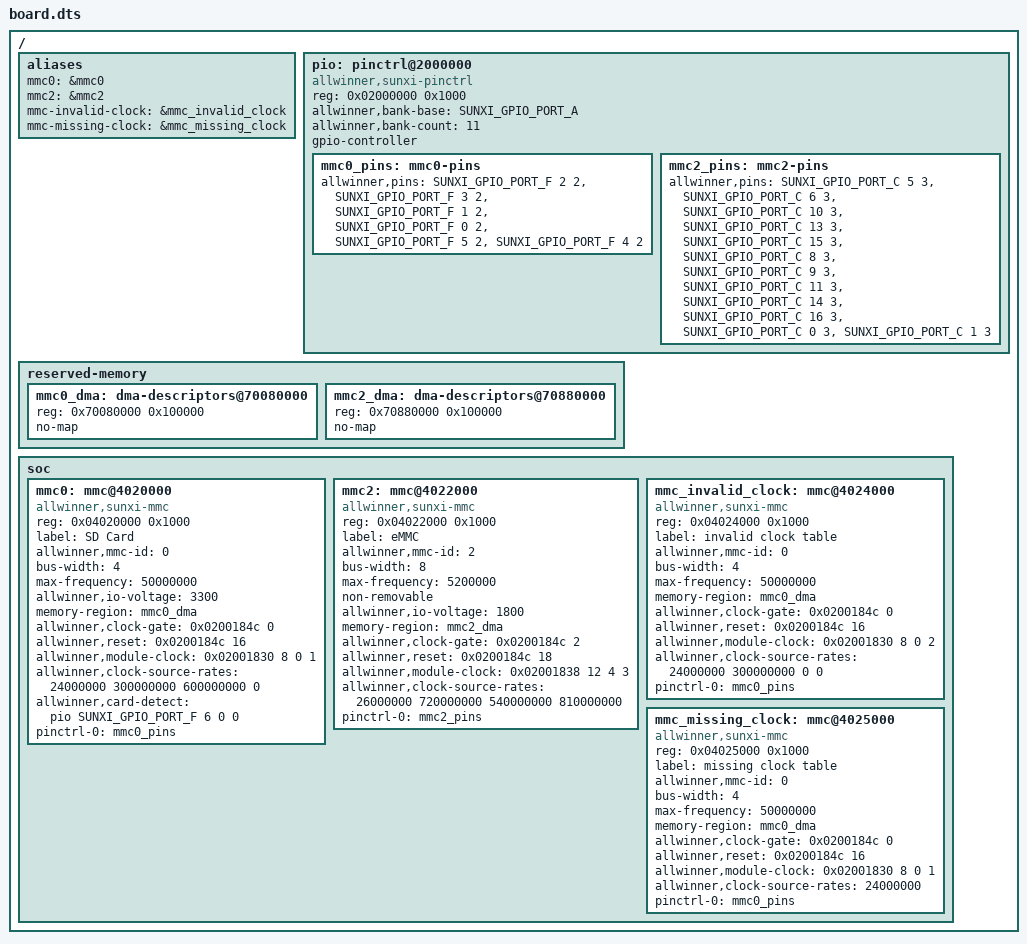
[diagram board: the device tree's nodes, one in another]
/dts-v1/;

#include <dt-bindings/gpio/sunxi-gpio.h>

/ {
	#address-cells = <1>;
	#size-cells = <1>;

		aliases {
			mmc0 = &mmc0;
			mmc2 = &mmc2;
			mmc-invalid-clock = &mmc_invalid_clock;
			mmc-missing-clock = &mmc_missing_clock;
	};

	pio: pinctrl@2000000 {
		compatible = "allwinner,sunxi-pinctrl";
		reg = <0x02000000 0x1000>;
		allwinner,bank-base = <SUNXI_GPIO_PORT_A>;
		allwinner,bank-count = <11>;
		#gpio-cells = <3>;
		gpio-controller;

		mmc0_pins: mmc0-pins {
			allwinner,pins =
				<SUNXI_GPIO_PORT_F 2 2>,
				<SUNXI_GPIO_PORT_F 3 2>,
				<SUNXI_GPIO_PORT_F 1 2>,
				<SUNXI_GPIO_PORT_F 0 2>,
				<SUNXI_GPIO_PORT_F 5 2>,
				<SUNXI_GPIO_PORT_F 4 2>;
		};

		mmc2_pins: mmc2-pins {
			allwinner,pins =
				<SUNXI_GPIO_PORT_C 5 3>,
				<SUNXI_GPIO_PORT_C 6 3>,
				<SUNXI_GPIO_PORT_C 10 3>,
				<SUNXI_GPIO_PORT_C 13 3>,
				<SUNXI_GPIO_PORT_C 15 3>,
				<SUNXI_GPIO_PORT_C 8 3>,
				<SUNXI_GPIO_PORT_C 9 3>,
				<SUNXI_GPIO_PORT_C 11 3>,
				<SUNXI_GPIO_PORT_C 14 3>,
				<SUNXI_GPIO_PORT_C 16 3>,
				<SUNXI_GPIO_PORT_C 0 3>,
				<SUNXI_GPIO_PORT_C 1 3>;
		};
	};

	reserved-memory {
		#address-cells = <1>;
		#size-cells = <1>;
		ranges;

		mmc0_dma: dma-descriptors@70080000 {
			reg = <0x70080000 0x100000>;
			no-map;
		};

		mmc2_dma: dma-descriptors@70880000 {
			reg = <0x70880000 0x100000>;
			no-map;
		};
	};

	soc {
		#address-cells = <1>;
		#size-cells = <1>;
		ranges;

		mmc0: mmc@4020000 {
			compatible = "allwinner,sunxi-mmc";
			reg = <0x04020000 0x1000>;
			label = "SD Card";
			allwinner,mmc-id = <0>;
			bus-width = <4>;
			max-frequency = <50000000>;
			allwinner,io-voltage = <3300>;
			memory-region = <&mmc0_dma>;
			allwinner,clock-gate = <0x0200184c 0>;
			allwinner,reset = <0x0200184c 16>;
			allwinner,module-clock =
				<0x02001830 8 0 1>;
			allwinner,clock-source-rates =
				<24000000 300000000 600000000 0>;
			allwinner,card-detect =
				<&pio SUNXI_GPIO_PORT_F 6 0 0>;
			pinctrl-names = "default";
			pinctrl-0 = <&mmc0_pins>;
			status = "okay";
		};

		mmc2: mmc@4022000 {
			compatible = "allwinner,sunxi-mmc";
			reg = <0x04022000 0x1000>;
			label = "eMMC";
			allwinner,mmc-id = <2>;
			bus-width = <8>;
			max-frequency = <5200000>;
			non-removable;
			allwinner,io-voltage = <1800>;
			memory-region = <&mmc2_dma>;
			allwinner,clock-gate = <0x0200184c 2>;
			allwinner,reset = <0x0200184c 18>;
			allwinner,module-clock =
				<0x02001838 12 4 3>;
			allwinner,clock-source-rates =
				<26000000 720000000 540000000 810000000>;
			pinctrl-names = "default";
			pinctrl-0 = <&mmc2_pins>;
			status = "okay";
		};

		mmc_invalid_clock: mmc@4024000 {
			compatible = "allwinner,sunxi-mmc";
			reg = <0x04024000 0x1000>;
			label = "invalid clock table";
			allwinner,mmc-id = <0>;
			bus-width = <4>;
			max-frequency = <50000000>;
			memory-region = <&mmc0_dma>;
			allwinner,clock-gate = <0x0200184c 0>;
			allwinner,reset = <0x0200184c 16>;
			allwinner,module-clock = <0x02001830 8 0 2>;
			allwinner,clock-source-rates =
				<24000000 300000000 0 0>;
			pinctrl-names = "default";
			pinctrl-0 = <&mmc0_pins>;
			status = "okay";
		};

		mmc_missing_clock: mmc@4025000 {
			compatible = "allwinner,sunxi-mmc";
			reg = <0x04025000 0x1000>;
			label = "missing clock table";
			allwinner,mmc-id = <0>;
			bus-width = <4>;
			max-frequency = <50000000>;
			memory-region = <&mmc0_dma>;
			allwinner,clock-gate = <0x0200184c 0>;
			allwinner,reset = <0x0200184c 16>;
			allwinner,module-clock = <0x02001830 8 0 1>;
			allwinner,clock-source-rates = <24000000>;
			pinctrl-names = "default";
			pinctrl-0 = <&mmc0_pins>;
			status = "okay";
		};
	};
};
